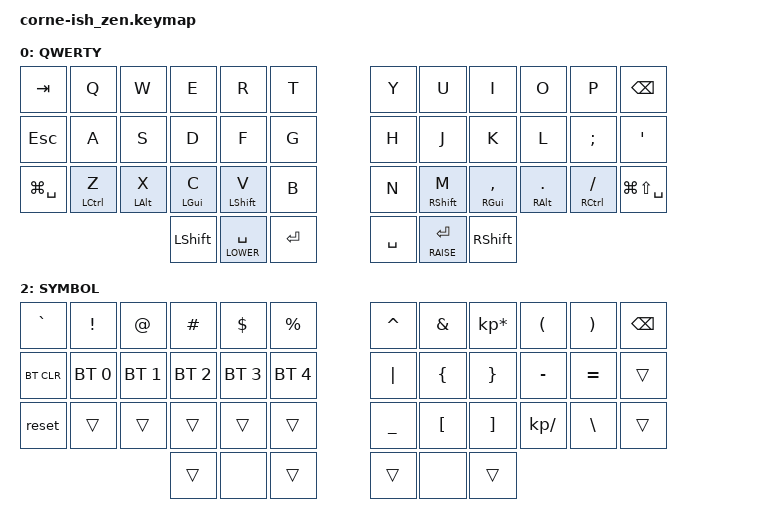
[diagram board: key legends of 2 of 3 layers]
/*
*
* Copyright (c) 2021 Darryl deHaan
* SPDX-License-Identifier: MIT
*
*/

#include <behaviors.dtsi>
#include <dt-bindings/zmk/keys.h>
#include <dt-bindings/zmk/bt.h>

#define QWERTY 0
#define LOWER    1
#define RAISE    2

// default layer uses home row mods https://precondition.github.io/home-row-mods
// uses CAGS modifier order


/ {
        behaviors {
                hml: homerow_mods_left {
                        compatible = "zmk,behavior-hold-tap";
                        label = "HOMEROW_MODS_LEFT";
                        #binding-cells = <2>;
                        tapping-term-ms = <150>;
                        quick_tap_ms = <0>;
                        flavor = "balanced";
                        bindings = <&kp>, <&kp>;
                        hold-trigger-key-positions = <6 7 8 9 10 11 
                                                      18 19 20 21 22 23
                                                      30 31 32 33 34 35
                                                      39 40 41
                                                     >;    // <---[[right-hand keys are allowed]]
                };
                hmr: homerow_mods_right {
                        compatible = "zmk,behavior-hold-tap";
                        label = "HOMEROW_MODS_RIGHT";
                        #binding-cells = <2>;
                        tapping-term-ms = <150>;
                        quick_tap_ms = <0>;
                        flavor = "balanced";
                        bindings = <&kp>, <&kp>;
                        hold-trigger-key-positions = <0 1 2 3 4 5
                                                      12 13 14 15 16 17
                                                      24 25 26 27 28 29
                                                      36 37 38
                                                      >;    // <---[[left-hand keys are allowed]]
                };
        };
        keymap {
                compatible = "zmk,keymap";

                default_layer {
                        label = "QWERTY";
// pos 0     1     2     3     4     5         6     7     8      9     10    11 
// -----------------------------------------------------------------------------------------
// |  TAB |  Q  |  W  |  E  |  R  |  T  |   |  Y  |  U   |  I  |  O  |  P  | BKSP |
// | ESC  |  A  |  S  |  D  |  F  |  G  |   |  H  |  J   |  K  |  L  |  ;  |  '   |
// | C-S- |  Z  |  X  |  C  |  V  |  B  |   |  N  |  M   |  ,  |  .  |  /  | C-   |
//                    | TAB | LWR | ENT |   | SPC | RSE  | SHFT |
                        bindings = <
&kp TAB       &kp Q       &kp W      &kp E      &kp R            &kp T        &kp Y     &kp U         &kp I           &kp O         &kp P           &kp BSPC
&kp ESC       &kp A       &kp S      &kp D      &kp F            &kp G        &kp H     &kp J         &kp K           &kp L         &kp SEMI        &kp SQT
&kp LG(SPACE) &hml LCTRL Z &hml LALT X &hml LGUI C &hml LSHIFT V &kp B        &kp N     &hmr RSHIFT M &hmr RGUI COMMA &hmr RALT DOT &hmr RCTRL FSLH &kp LG(LS(SPACE))
                          &kp LSHFT    &lt LOWER SPACE  &kp RET               &kp SPACE   &lt RAISE RET  &kp RSHFT
                        >;
                };

                lower_layer {
                        label = "LOWER";
// -----------------------------------------------------------------------------------------
// |  `   |  1  |  2  |  3  |  4  |  5  |   |  6  |  7  |  8   |  9   |  0  | BKSP |
// | BTCLR| BT1 | BT2 | BT3 | BT4 | BT5 |   | LFT | DWN |  UP  | RGT  |     |      |
// | SHFT |     |     |     |     |     |   | << | vol- | vol+ | >>   |     |      |  
//                    | GUI |     | SPC |   | ENT |     | ALT  |
                        bindings = <
   &kp GRAVE  &kp N1       &kp N2       &kp N3       &kp N4       &kp N5         &kp N6     &kp N7       &kp N8       &kp N9       &kp N0     &kp BSPC
   &trans     &kp F6       &kp F7       &kp F8       &kp F9       &kp F10        &kp LEFT   &kp DOWN     &kp UP       &kp RIGHT    &trans     &trans   
   &trans     &kp F1       &kp F2       &kp F3       &kp F4       &kp F5         &kp C_PREV &kp C_VOL_DN &kp C_VOL_UP &kp C_NEXT   &trans 
                          	        &trans     &none       &trans      &trans  &none     &trans
                        >;
                };

                raise_layer {
                        label = "SYMBOL";
// -----------------------------------------------------------------------------------------
// |   `  |  !  |  @  |  #  |  $  |  %  |   |  ^  |  &  |  *  |  (  |  )  | BKSP |
// | BTCLR| BT1 | BT2 | BT3 | BT4 | BT5 |   | "|" |  {  |  }  |  -  |  =  |      |
// |      |     |     |     |     |     |   |     |  [  |  ]  |  /  |  \  |      |
//                    | GUI |     | SPC |   | ENT |     | ALT |
                        bindings = <
   &kp GRAVE  &kp EXCL &kp AT &kp HASH &kp DLLR &kp PRCNT   &kp CARET &kp AMPS  &kp KP_MULTIPLY &kp LPAR     &kp RPAR      &kp BSPC
   &bt BT_CLR &bt BT_SEL 0 &bt BT_SEL 1 &bt BT_SEL 2 &bt BT_SEL 3 &bt BT_SEL 4      &kp PIPE  &kp LBRC  &kp RBRC        &kp MINUS    &kp EQUAL     &trans
   &reset     &trans   &trans &trans   &trans   &trans      &kp UNDER &kp LBKT  &kp RBKT        &kp KP_SLASH &kp BACKSLASH &trans
                    	     &trans &none   &trans   &trans   &none    &trans
                        >;
                };
        };
};
